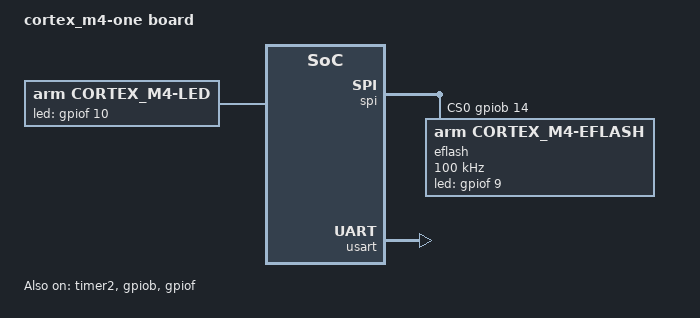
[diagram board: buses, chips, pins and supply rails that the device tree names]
/dts-v1/;
/include/ "skeleton.dtsi"
#include <dt-bindings/gpio/gpio.h>
/ {
	model = "cortex_m4-one board";
	compatible = "arm,cortex_m4";

	chosen {
		bootargs = "root=/dev/ram mem=1M@0x68000000 console=ttyAMA0,115200 root=/dev/mtdblock1 rootfstype=romfs mtdparts=cortex_m4_iflash:4k(dtb),256K(rootfs)";
		stdout-path = "serial0:115200n8";
	};

	nvic: nv-interrupt-controller  {
		compatible = "arm,armv7m-nvic";
		interrupt-controller;
		#interrupt-cells = <1>;
		reg = <0xe000e100 0xc00>;
	};

	soc {
		#address-cells = <1>;
		#size-cells = <1>;
		compatible = "simple-bus";
		interrupt-parent = <&nvic>;
		ranges;
		
		timer2: timer@40000000 {
			compatible = "arm,cortex_m4-timer";
			reg = <0x40000000 0x000>;
			interrupts = <28>;
			status = "okay";
		};

		/*
		gpioa: gpio@40020000 {
			compatible = "arm,cortex_m4-gpio";
			reg = <0x40020000 0x400>;
			gpio-controller;
			#gpio-cells = <2>;
			status = "okay";
		};
		*/
		
		gpiob: gpio@40020400 {
			compatible = "arm,cortex_m4-gpio";
			reg = <0x40020400 0x400>;
			gpio-controller;
			#gpio-cells = <2>;
			status = "okay";
		};

		/*
		gpioc: gpio@40020800 {
			compatible = "arm,cortex_m4-gpio";
			reg = <0x40020800 0x400>;
			gpio-controller;
			#gpio-cells = <2>;
			status = "okay";
		};

		gpiod: gpio@40020c00 {
			compatible = "arm,cortex_m4-gpio";
			reg = <0x40020c00 0x400>;
			gpio-controller;
			#gpio-cells = <2>;
			status = "okay";
		};

		gpioe: gpio@40021000 {
			compatible = "arm,cortex_m4-gpio";
			reg = <0x40021000 0x400>;
			gpio-controller;
			#gpio-cells = <2>;
			status = "okay";
		};
		*/
		
		gpiof: gpio@40021400 {
			compatible = "arm,cortex_m4-gpio";
			reg = <0x40021400 0x400>;
			gpio-controller;
			#gpio-cells = <2>;
			status = "okay";
		};

		/*
		gpiog: gpio@40021800 {
			compatible = "arm,cortex_m4-gpio";
			reg = <0x40021800 0x400>;
			gpio-controller;
			#gpio-cells = <2>;
			status = "okay";
		};

		gpioh: gpio@40021c00 {
			compatible = "arm,cortex_m4-gpio";
			reg = <0x40021c00 0x400>;
			gpio-controller;
			#gpio-cells = <2>;
			status = "okay";
		};

		gpioi: gpio@40022000 {
			compatible = "arm,cortex_m4-gpio";
			reg = <0x40022000 0x400>;
			gpio-controller;
			#gpio-cells = <2>;
			status = "okay";
		};
		*/

		spi: spi@0 {
			compatible = "arm,cortex_m4-spi";
			reg = <0x40013000 0x400>;
			cs-gpios = <&gpiob 14 GPIO_ACTIVE_HIGH>;
			num-chipselects = <1>;
			#address-cells = <1>;
			#size-cells = <0>;
			status = "okay";

			eflash: eflash@0 {
				compatible = "arm,cortex_m4-eflash";
				reg = <0>;
				led-gpios = <&gpiof 9 GPIO_ACTIVE_HIGH>;
				spi-max-frequency = <100000>;
				spi-tx-bus-width = <0x01>;
				spi-rx-bus-width = <0x01>;
				spi-cpol;
				spi-cpha;
			};
		};	

		usart: serial@40004400 {
			compatible = "arm,cortex_m4-usart";
			reg = <0x40004400 0x400>;
			interrupts = <38>;
			status = "okay";
		};

		led: led@0 {
			compatible = "arm,cortex_m4-led";
			led-gpios = <&gpiof 10 GPIO_ACTIVE_HIGH>;
			status = "okay";
		};
	};
};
